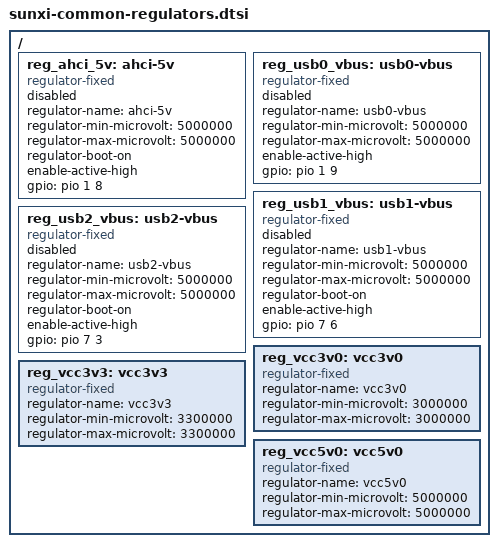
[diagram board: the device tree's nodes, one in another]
#include <dt-bindings/gpio/gpio.h>
/ {
	reg_ahci_5v: ahci-5v {
		compatible = "regulator-fixed";
		regulator-name = "ahci-5v";
		regulator-min-microvolt = <5000000>;
		regulator-max-microvolt = <5000000>;
		regulator-boot-on;
		enable-active-high;
		gpio = <&pio 1 8 GPIO_ACTIVE_HIGH>;
		status = "disabled";
	};
	reg_usb0_vbus: usb0-vbus {
		compatible = "regulator-fixed";
		regulator-name = "usb0-vbus";
		regulator-min-microvolt = <5000000>;
		regulator-max-microvolt = <5000000>;
		enable-active-high;
		gpio = <&pio 1 9 GPIO_ACTIVE_HIGH>;
		status = "disabled";
	};
	reg_usb1_vbus: usb1-vbus {
		compatible = "regulator-fixed";
		regulator-name = "usb1-vbus";
		regulator-min-microvolt = <5000000>;
		regulator-max-microvolt = <5000000>;
		regulator-boot-on;
		enable-active-high;
		gpio = <&pio 7 6 GPIO_ACTIVE_HIGH>;
		status = "disabled";
	};
	reg_usb2_vbus: usb2-vbus {
		compatible = "regulator-fixed";
		regulator-name = "usb2-vbus";
		regulator-min-microvolt = <5000000>;
		regulator-max-microvolt = <5000000>;
		regulator-boot-on;
		enable-active-high;
		gpio = <&pio 7 3 GPIO_ACTIVE_HIGH>;
		status = "disabled";
	};
	reg_vcc3v0: vcc3v0 {
		compatible = "regulator-fixed";
		regulator-name = "vcc3v0";
		regulator-min-microvolt = <3000000>;
		regulator-max-microvolt = <3000000>;
	};
	reg_vcc3v3: vcc3v3 {
		compatible = "regulator-fixed";
		regulator-name = "vcc3v3";
		regulator-min-microvolt = <3300000>;
		regulator-max-microvolt = <3300000>;
	};
	reg_vcc5v0: vcc5v0 {
		compatible = "regulator-fixed";
		regulator-name = "vcc5v0";
		regulator-min-microvolt = <5000000>;
		regulator-max-microvolt = <5000000>;
	};
};
